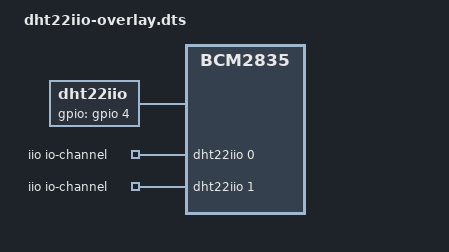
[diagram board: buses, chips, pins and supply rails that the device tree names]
/dts-v1/;
/plugin/;

/ {
    compatible = "brcm,bcm2835";  // For Raspberry Pi or relevant SoC

    fragment@0 {
        // target = <&gpio>; // can modify existing gpio overlay
        target-path = "/";
        __overlay__ {
            dht22iio: dht22iio@4 { // hex of default pin # 0x4 == 4
                compatible = "dht22iio";
                gpios = <&gpio 4 0>; // default pin 4
                status = "okay";
                #io-channel-cells = <1>;
            };


     		iio: dht22iio-hwmon@4 { // second name is whatever I want, I should update addy too but lets break it before I do that
				compatible = "iio-hwmon";
				status = "okay";
				io-channels = <&dht22iio 0>, <&dht22iio 1>;
			};

        };
    };

    __overrides__ {
        gpio_pin = <&dht22iio>,"gpios: 4", // overwrite gpios pin (starting at 4th byte, IIUC 2nd word)
                   <&dht22iio>,"reg: 0", // changes @address => touch_sensor_unified@gpio_pin
                   <&iio>,"reg: 0"; // also update address for hwmon interface!!! yay worked
    };

};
